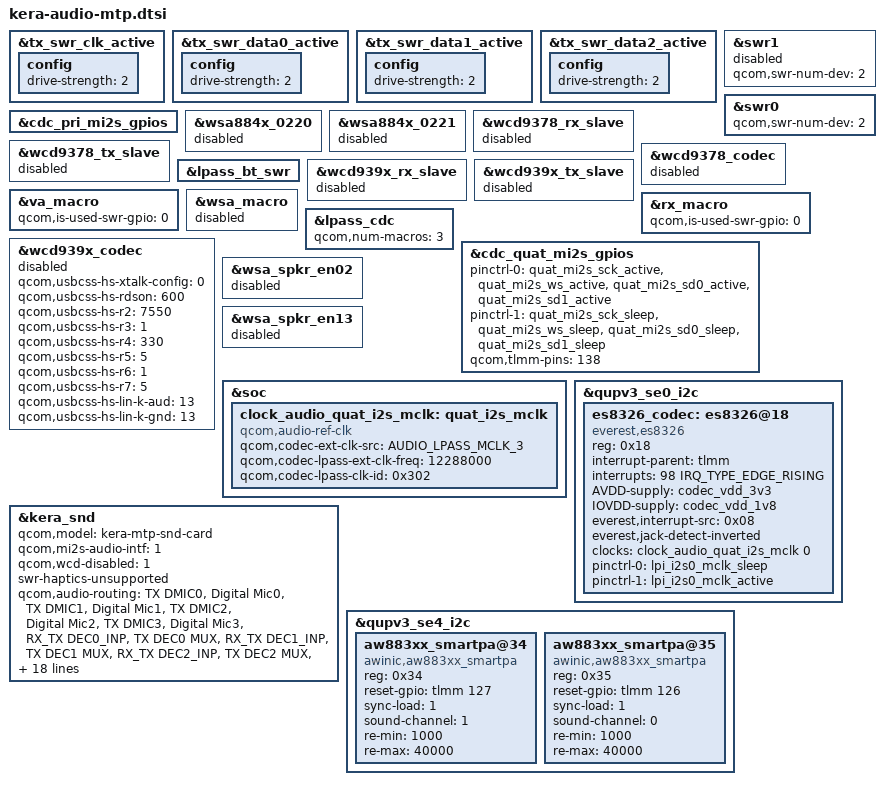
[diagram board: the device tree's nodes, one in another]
// SPDX-License-Identifier: BSD-3-Clause
/*
 * Copyright (c) Qualcomm Technologies, Inc. and/or its subsidiaries.
 */

#include "kera-audio-overlay.dtsi"
#include "kera-audio-lpass-reg.dtsi"

&tx_swr_clk_active {
	config {
		drive-strength = <2>;
	};
};

&tx_swr_data0_active {
	config {
		drive-strength = <2>;
	};
};

&tx_swr_data1_active {
	config {
		drive-strength = <2>;
	};
};

&tx_swr_data2_active {
	config {
		drive-strength = <2>;
	};
};

&cdc_pri_mi2s_gpios {
	status = "okay";
};

&swr1 {
	status = "disabled";
	qcom,swr-num-dev = <2>;
};

&swr0 {
	qcom,swr-num-dev = <2>;
};

&wsa884x_0220 {
	status = "disabled";
};

&wsa884x_0221 {
	status = "disabled";
};

&wcd9378_rx_slave {
	status = "disabled";
};

&wcd9378_tx_slave {
	status = "disabled";
};

&wcd9378_codec {
	status = "disabled";
};

&lpass_bt_swr {
	status = "okay";
};

&wcd939x_rx_slave {
	status = "disabled";
};

&wcd939x_tx_slave {
	status = "disabled";
};

&va_macro {
	qcom,is-used-swr-gpio = <0>;
	/delete-property/ qcom,va-swr-gpios;
};

&rx_macro {
	qcom,is-used-swr-gpio = <0>;
	/delete-property/ qcom,rx-swr-gpios;
};

&wsa_macro {
    status = "disabled";
};

&lpass_cdc {
	qcom,num-macros = <3>;
};

&wcd939x_codec {
	status = "disabled";
	/* 0 for digital crosstalk disabled,
	 * 1 for digital crosstalk with local sensed a-xtalk enabled, and
	 * 2 for digital crosstalk with remote sensed a-xtalk enabled.
	 */
	qcom,usbcss-hs-xtalk-config = <0>;
	qcom,usbcss-hs-rdson = <600>;
	qcom,usbcss-hs-r2 = <7550>;
	qcom,usbcss-hs-r3 = <1>;
	qcom,usbcss-hs-r4 = <330>;
	qcom,usbcss-hs-r5 = <5>;
	qcom,usbcss-hs-r6 = <1>;
	qcom,usbcss-hs-r7 = <5>;
	qcom,usbcss-hs-lin-k-aud = <13>;
	qcom,usbcss-hs-lin-k-gnd = <13>;
};

&cdc_quat_mi2s_gpios {
	status = "okay";
	pinctrl-0 = <&quat_mi2s_sck_active &quat_mi2s_ws_active
			&quat_mi2s_sd0_active &quat_mi2s_sd1_active>;
			//&lpi_i2s0_mclk_active>;
	pinctrl-1 = <&quat_mi2s_sck_sleep &quat_mi2s_ws_sleep
			&quat_mi2s_sd0_sleep &quat_mi2s_sd1_sleep>;
			//&lpi_i2s0_mclk_sleep>;
	qcom,tlmm-pins = <138>;
};

&wsa_spkr_en02 {
	status = "disabled";
};

&wsa_spkr_en13 {
	status = "disabled";
};

&soc {
	clock_audio_quat_i2s_mclk: quat_i2s_mclk {
		compatible = "qcom,audio-ref-clk";
		qcom,codec-ext-clk-src = <AUDIO_LPASS_MCLK_3>;
		qcom,codec-lpass-ext-clk-freq = <12288000>;
		qcom,codec-lpass-clk-id = <0x302>;
		#clock-cells = <1>;
	};
};

&qupv3_se0_i2c {
	status = "okay";

	es8326_codec: es8326@18 {
		compatible = "everest,es8326";
		reg = <0x18>;
		interrupt-parent = <&tlmm>;
		interrupts = <98 IRQ_TYPE_EDGE_RISING>;
		AVDD-supply = <&codec_vdd_3v3>;
		IOVDD-supply = <&codec_vdd_1v8>;
		#sound-dai-cells = <0>;
		everest,interrupt-src = /bits/ 8 <0x08>;
		everest,jack-detect-inverted;
		clocks = <&clock_audio_quat_i2s_mclk 0>;
		clock-names = "mclk";
		pinctrl-names = "sleep", "active";
		pinctrl-0 = <&lpi_i2s0_mclk_sleep>;
		pinctrl-1 = <&lpi_i2s0_mclk_active>;
	};
};

&kera_snd {
	qcom,model = "kera-mtp-snd-card";
	qcom,mi2s-audio-intf = <1>;
	qcom,wcd-disabled = <1>;
	swr-haptics-unsupported;
	qcom,audio-routing =
			"TX DMIC0", "Digital Mic0",
			"TX DMIC1", "Digital Mic1",
			"TX DMIC2", "Digital Mic2",
			"TX DMIC3", "Digital Mic3",
			"RX_TX DEC0_INP", "TX DEC0 MUX",
			"RX_TX DEC1_INP", "TX DEC1 MUX",
			"RX_TX DEC2_INP", "TX DEC2 MUX",
			"RX_TX DEC3_INP", "TX DEC3 MUX",
			"VA DMIC0", "Digital Mic0",
			"VA DMIC1", "Digital Mic1",
			"VA DMIC2", "Digital Mic2",
			"VA DMIC3", "Digital Mic3";
	qcom,cdc-dmic01-gpios = <&cdc_dmic01_gpios>;
	qcom,cdc-dmic23-gpios = <&cdc_dmic23_gpios>;
	qcom,msm_audio_ssr_devs = <&audio_gpr>, <&lpi_tlmm>,
				<&lpass_cdc>;
	asoc-codec  = <&stub_codec>, <&lpass_cdc>, <&es8326_codec>;
	asoc-codec-names = "msm-stub-codec.1", "lpass-cdc", "es8326_codec";
	qcom,wsa-max-devs = <0>;
	qcom,pri-mi2s-gpios = <&cdc_pri_mi2s_gpios>;
	qcom,quat-mi2s-gpios = <&cdc_quat_mi2s_gpios>;
	qcom,msm-mbhc-hphl-swh = <1>;
	qcom,msm-mbhc-gnd-swh = <1>;
	qcom,msm-mbhc-hs-mic-max-threshold-mv = <1670>;
};

&qupv3_se4_i2c {
       status = "ok";
       aw883xx_smartpa@34 {
               compatible = "awinic,aw883xx_smartpa";
               reg = <0x34>;
               reset-gpio = <&tlmm 127 0>;
               //irq-gpio = <&tlmm 30 0>;
               sync-load = <1>;
               sound-channel = <1>;//left
               re-min = <1000>;
               re-max= <40000>;
               status = "okay";
       };
       aw883xx_smartpa@35 {
               compatible = "awinic,aw883xx_smartpa";
               reg = <0x35>;
               reset-gpio = <&tlmm 126 0>;
               //irq-gpio = <&tlmm 120 0>;
               sync-load = <1>;
               sound-channel = <0>;//right
               re-min = <1000>;
               re-max= <40000>;
               status = "okay";
       };
};
